# ISP_CCP2B register map
Vendor: Texas Instruments
Peripheral module from a debugger description file (folder omap36xx).
Registers are 32-bit, read-write, reset values left out (the file's numbers can be read two ways) unless marked. A register's access mark holds for its fields unless they carry their own. Offsets are as the file gives them; lines under a group give offsets from that group; [hi:lo] are bit positions; {n}, {i} and the like mark numbered series; 'fields as' and 'values as' point back to an identical list; <NAME> marks a mode.

## ISP_CCP2B
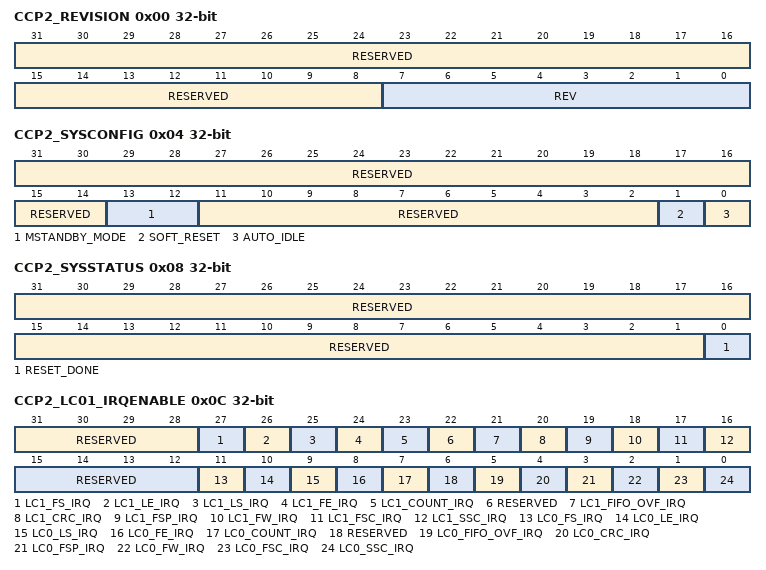
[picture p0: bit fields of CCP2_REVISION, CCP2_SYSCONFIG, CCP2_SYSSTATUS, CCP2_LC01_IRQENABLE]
0x00 CCP2_REVISION ro — MODULE REVISION This register contains the IP revision code in binary coded digital. For example, 0x01 = revision 0.1 and 0x21 = revision 2.1
  [31:8] RESERVED — Write 0's for future compatibility.Reads returns 0.
  [7:0] REV — IP revision [7:4] Major revision[3:0] Minor revision
0x04 CCP2_SYSCONFIG — SYSTEM CONFIGURATION REGISTERThis register is the Interconnect-socket system configuration register.
  [31:14] RESERVED — Write 0s for future compatibility. Read returns 0.
  [13:12] MSTANDBY_MODE — Sets the behavior of the master port power management signals
    0=Force-standby. MStandby is asserted only when the module is disabled.; 1=No-standby. MStandby is never asserted.; 2=Smart-standby: MStandby is asserted based on the activity of the module. The module tries to go to standby during the vertical blanking period.
  [11:2] RESERVED — Write 0s for future compatibility. Read returns 0.
  [1] SOFT_RESET — Software reset. Set the bit to 1 to trigger a module reset. The bit is automatically reset by the hardware. Read returns 0.
    0=Normal mode; 1=The module is reset
  [0] AUTO_IDLE — Internal Interconnect clock-gating strategy
    0=Interconnect clock is free-running; 1=Automatic Interconnect clock-gating strategy is applied based on Interconnect interface activity
0x08 CCP2_SYSSTATUS ro — SYSTEM STATUS REGISTER This register provides status information about the module, excluding interrupt status information.
  [31:1] RESERVED — Write 0s for future compatibility. Read returns 0.
  [0] RESET_DONE — Internal reset monitoring
    0=Internal module reset is ongoing; 1=Reset complete
0x0C CCP2_LC01_IRQENABLE — INTERRUPT ENABLE REGISTER - LOGICAL CHANNELS 0 and 1 This register regroups all the events related to logical channel 0 and logical channel 1. The events related to logical channel 0 trigger SINTERRUPTN[0]. The events related to logical channel 1 trigger SINTERRUPTN[1]. The channel is enabled for events to be generated on that channel.
  [31:28] RESERVED — Write 0s for future compatibility. Read returns 0.
  [27] LC1_FS_IRQ — Logical channel 1 - Frame start synchronization code detection
    0=Event is masked; 1=Event generates an interrupt when it occurs
  [26] LC1_LE_IRQ — Logical channel 1 - Line end synchronization code detection
    values as LC1_FS_IRQ
  [25] LC1_LS_IRQ — Logical channel 1 - Line start synchronization code detection
    values as LC1_FS_IRQ
  [24] LC1_FE_IRQ — Logical channel 1 - Frame end synchronization code detection
    values as LC1_FS_IRQ
  [23] LC1_COUNT_IRQ — Logical channel 1 - Frame counter reached
    values as LC1_FS_IRQ
  [22] RESERVED — Write 0s for future compatibility. Read returns 0.
  [21] LC1_FIFO_OVF_IRQ — Logical channel 1 - FIFO overflow error
    values as LC1_FS_IRQ
  [20] LC1_CRC_IRQ — Logical channel 1 - CRC error
    values as LC1_FS_IRQ
  [19] LC1_FSP_IRQ — Logical channel 1 - FSP error
    values as LC1_FS_IRQ
  [18] LC1_FW_IRQ — Logical channel 1 - Frame width error
    values as LC1_FS_IRQ
  [17] LC1_FSC_IRQ — Logical channel 1 - False synchronization code error
    values as LC1_FS_IRQ
  [16] LC1_SSC_IRQ — Logical channel 1 - Shifted synchronization code error.\This interrupt can be triggered if the PHY is set in parallel mode (CCP2_CTRL.IO_OUT_SEL = 1).
    values as LC1_FS_IRQ
  [15:12] RESERVED — Write 0s for future compatibility. Read returns 0.
  [11] LC0_FS_IRQ — Logical channel 0 - Frame start synchronization code detection
    values as LC1_FS_IRQ
  [10] LC0_LE_IRQ — Logical channel 0 - Line end synchronization code detection
    values as LC1_FS_IRQ
  [9] LC0_LS_IRQ — Logical channel 0 - Line start synchronization code detection
    values as LC1_FS_IRQ
  [8] LC0_FE_IRQ — Logical channel 0 - Frame end synchronization code detection
    values as LC1_FS_IRQ
  [7] LC0_COUNT_IRQ — Logical channel 0 - Frame counter reached
    values as LC1_FS_IRQ
  [6] RESERVED — Write 0s for future compatibility. Read returns 0.
  [5] LC0_FIFO_OVF_IRQ — Logical channel 0 - FIFO overflow error
    values as LC1_FS_IRQ
  [4] LC0_CRC_IRQ — Logical channel 0 - CRC error
    values as LC1_FS_IRQ
  [3] LC0_FSP_IRQ — Logical channel 0 - FSP error
    values as LC1_FS_IRQ
  [2] LC0_FW_IRQ — Logical channel 0 - Frame width error
    values as LC1_FS_IRQ
  [1] LC0_FSC_IRQ — Logical channel 0 - False synchronization code error
    values as LC1_FS_IRQ
  [0] LC0_SSC_IRQ — Logical channel 0 - Shifted synchronization code errorThis interrupt can be triggered if the PHY is set in parallel mode (CCP2_CTRL.IO_OUT_SEL = 1).
    values as LC1_FS_IRQ
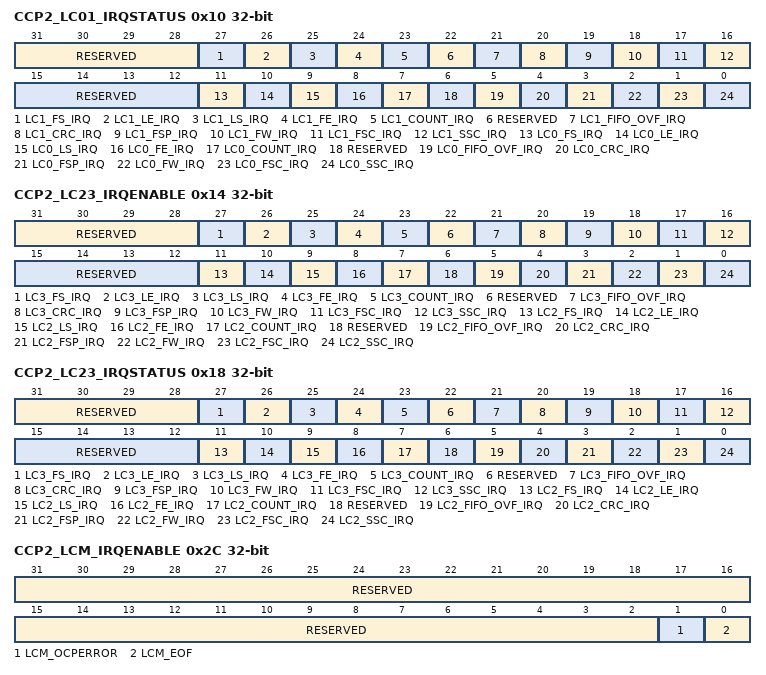
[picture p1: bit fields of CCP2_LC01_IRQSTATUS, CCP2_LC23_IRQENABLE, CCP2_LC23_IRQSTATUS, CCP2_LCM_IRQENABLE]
0x10 CCP2_LC01_IRQSTATUS access not given — INTERRUPT STATUS REGISTER - LOGICAL CHANNELS 0 and 1 This register regroups all the events related to logical channel 0 and logical channel 1. The events related to logical channel 0 trigger SINTERRUPTN[0]. The events related to logical channel 1 trigger SINTERRUPTN[1]. The channel is enabled for events to be generated on that channel.
  [31:28] RESERVED rw — Write 0s for future compatibility. Read returns 0.
  [27] LC1_FS_IRQ — Logical channel 1 - Frame start synchronization code detection status (access RW 1toClr)
    0=READS: Event is false. WRITES: Status bit unchanged; 1=READS: Event is true (pending). WRITES: Status bit is reset.
  [26] LC1_LE_IRQ — Logical channel 1 - Line end synchronization code detection status (access RW 1toClr)
    values as LC1_FS_IRQ
  [25] LC1_LS_IRQ — Logical channel 1 - Line start synchronization code detection status (access RW 1toClr)
    values as LC1_FS_IRQ
  [24] LC1_FE_IRQ — Logical channel 1 - Frame end synchronization code detection status (access RW 1toClr)
    values as LC1_FS_IRQ
  [23] LC1_COUNT_IRQ — Logical channel 1 - Frame counter reached status (access RW 1toClr)
    values as LC1_FS_IRQ
  [22] RESERVED rw — Write 0s for future compatibility. Read returns 0.
  [21] LC1_FIFO_OVF_IRQ — Logical channel 1 - FIFO overflow error status (access RW 1toClr)
    values as LC1_FS_IRQ
  [20] LC1_CRC_IRQ — Logical channel 1 - CRC error status (access RW 1toClr)
    values as LC1_FS_IRQ
  [19] LC1_FSP_IRQ — Logical channel 1 - FSP error status (access RW 1toClr)
    values as LC1_FS_IRQ
  [18] LC1_FW_IRQ — Logical channel 1 - Frame width error status (access RW 1toClr)
    values as LC1_FS_IRQ
  [17] LC1_FSC_IRQ — Logical channel 1 - False synchronization code error status (access RW 1toClr)
    values as LC1_FS_IRQ
  [16] LC1_SSC_IRQ — Logical channel 1 - Shifted synchronization code error status (access RW 1toClr)
    values as LC1_FS_IRQ
  [15:12] RESERVED rw — Write 0s for future compatibility. Read returns 0.
  [11] LC0_FS_IRQ — Logical channel 0 - Frame start synchronization code detection status (access RW 1toClr)
    values as LC1_FS_IRQ
  [10] LC0_LE_IRQ — Logical channel 0 - Line end synchronization code detection status (access RW 1toClr)
    values as LC1_FS_IRQ
  [9] LC0_LS_IRQ — Logical channel 0 - Line start synchronization code detection status (access RW 1toClr)
    values as LC1_FS_IRQ
  [8] LC0_FE_IRQ — Logical channel 0 - Frame end synchronization code detection status (access RW 1toClr)
    values as LC1_FS_IRQ
  [7] LC0_COUNT_IRQ — Logical channel 0 - Frame counter reached status (access RW 1toClr)
    values as LC1_FS_IRQ
  [6] RESERVED rw — Write 0s for future compatibility. Read returns 0.
  [5] LC0_FIFO_OVF_IRQ — Logical channel 0 - FIFO overflow error status (access RW 1toClr)
    values as LC1_FS_IRQ
  [4] LC0_CRC_IRQ — Logical channel 0 - CRC error status (access RW 1toClr)
    values as LC1_FS_IRQ
  [3] LC0_FSP_IRQ — Logical channel 0 - FSP error status (access RW 1toClr)
    values as LC1_FS_IRQ
  [2] LC0_FW_IRQ — Logical channel 0 - Frame width error status (access RW 1toClr)
    values as LC1_FS_IRQ
  [1] LC0_FSC_IRQ — Logical channel 0 - False synchronization code error status (access RW 1toClr)
    values as LC1_FS_IRQ
  [0] LC0_SSC_IRQ — Logical channel 0 - Shifted synchronization code error status (access RW 1toClr)
    values as LC1_FS_IRQ
0x14 CCP2_LC23_IRQENABLE — INTERRUPT ENABLE REGISTER - LOGICAL CHANNELS 2 and 3 This register regroups all the events related to logical channel 2 and logical channel 3. The events related to logical channel 2 trigger SINTERRUPTN[2]. The events related to logical channel 3 trigger SINTERRUPTN[3]. The channel is enabled for events to be generated on that channel.
  [31:28] RESERVED — Write 0s for future compatibility. Read returns 0.
  [27] LC3_FS_IRQ — Logical channel 3 - Frame start synchronization code detection
    values as CCP2_LC01_IRQENABLE.LC1_FS_IRQ
  [26] LC3_LE_IRQ — Logical channel 3 - Line end synchronization code detection
    values as CCP2_LC01_IRQENABLE.LC1_FS_IRQ
  [25] LC3_LS_IRQ — Logical channel 3 - Line start synchronization code detection
    values as CCP2_LC01_IRQENABLE.LC1_FS_IRQ
  [24] LC3_FE_IRQ — Logical channel 3 - Frame end synchronization code detection
    values as CCP2_LC01_IRQENABLE.LC1_FS_IRQ
  [23] LC3_COUNT_IRQ — Logical channel 3 - Frame counter reached
    values as CCP2_LC01_IRQENABLE.LC1_FS_IRQ
  [22] RESERVED — Write 0s for future compatibility. Read returns 0.
  [21] LC3_FIFO_OVF_IRQ — Logical channel 3 - FIFO overflow error
    values as CCP2_LC01_IRQENABLE.LC1_FS_IRQ
  [20] LC3_CRC_IRQ — Logical channel 3 - CRC error
    values as CCP2_LC01_IRQENABLE.LC1_FS_IRQ
  [19] LC3_FSP_IRQ — Logical channel 3 - FSP error
    values as CCP2_LC01_IRQENABLE.LC1_FS_IRQ
  [18] LC3_FW_IRQ — Logical channel 3 - Frame width error
    values as CCP2_LC01_IRQENABLE.LC1_FS_IRQ
  [17] LC3_FSC_IRQ — Logical channel 3 - False synchronization code error
    values as CCP2_LC01_IRQENABLE.LC1_FS_IRQ
  [16] LC3_SSC_IRQ — Logical channel 3 - Shifted synchronization code errorThis interrupt can be triggered if the PHY is set in parallel mode (CCP2_CTRL.IO_OUT_SEL = 1).
    values as CCP2_LC01_IRQENABLE.LC1_FS_IRQ
  [15:12] RESERVED — Write 0s for future compatibility. Read returns 0.
  [11] LC2_FS_IRQ — Logical channel 2 - Frame start synchronization code detection
    values as CCP2_LC01_IRQENABLE.LC1_FS_IRQ
  [10] LC2_LE_IRQ — Logical channel 2 - Line end synchronization code detection
    values as CCP2_LC01_IRQENABLE.LC1_FS_IRQ
  [9] LC2_LS_IRQ — Logical channel 2 - Line start synchronization code detection
    values as CCP2_LC01_IRQENABLE.LC1_FS_IRQ
  [8] LC2_FE_IRQ — Logical channel 2 - Frame end synchronization code detection
    values as CCP2_LC01_IRQENABLE.LC1_FS_IRQ
  [7] LC2_COUNT_IRQ — Logical channel 2 - Frame counter reached
    values as CCP2_LC01_IRQENABLE.LC1_FS_IRQ
  [6] RESERVED — Write 0s for future compatibility. Read returns 0.
  [5] LC2_FIFO_OVF_IRQ — Logical channel 2 - FIFO overflow error
    values as CCP2_LC01_IRQENABLE.LC1_FS_IRQ
  [4] LC2_CRC_IRQ — Logical channel 2 - CRC error
    values as CCP2_LC01_IRQENABLE.LC1_FS_IRQ
  [3] LC2_FSP_IRQ — Logical channel 2 - FSP error
    values as CCP2_LC01_IRQENABLE.LC1_FS_IRQ
  [2] LC2_FW_IRQ — Logical channel 2 - Frame width error
    values as CCP2_LC01_IRQENABLE.LC1_FS_IRQ
  [1] LC2_FSC_IRQ — Logical channel 2 - False synchronization code error
    values as CCP2_LC01_IRQENABLE.LC1_FS_IRQ
  [0] LC2_SSC_IRQ — Logical channel 2 - Shifted synchronization code errorThis interrupt can be triggered if the PHY is set in parallel mode (CCP2_CTRL.IO_OUT_SEL = 1).
    values as CCP2_LC01_IRQENABLE.LC1_FS_IRQ
0x18 CCP2_LC23_IRQSTATUS access not given — INTERRUPT STATUS REGISTER - LOGICAL CHANNELS 2 and 3 This register regroups all the events related to logical channel 2 and logical channel 3. The events related to logical channel 2 trigger SINTERRUPTN[2]. The events related to logical channel 3 trigger SINTERRUPTN[3]. The channel is enabled for events to be generated on that channel.
  [31:28] RESERVED rw — Write 0s for future compatibility. Read returns 0.
  [27] LC3_FS_IRQ — Logical channel 3 - Frame start synchronization code detection status (access RW 1toClr)
    values as CCP2_LC01_IRQSTATUS.LC1_FS_IRQ
  [26] LC3_LE_IRQ — Logical channel 3 - Line end synchronization code detection status (access RW 1toClr)
    values as CCP2_LC01_IRQSTATUS.LC1_FS_IRQ
  [25] LC3_LS_IRQ — Logical channel 3 - Line start synchronization code detection status (access RW 1toClr)
    values as CCP2_LC01_IRQSTATUS.LC1_FS_IRQ
  [24] LC3_FE_IRQ — Logical channel 3 - Frame end synchronization code detection status (access RW 1toClr)
    values as CCP2_LC01_IRQSTATUS.LC1_FS_IRQ
  [23] LC3_COUNT_IRQ — Logical channel 3 - Frame counter reached status (access RW 1toClr)
    values as CCP2_LC01_IRQSTATUS.LC1_FS_IRQ
  [22] RESERVED rw — Write 0s for future compatibility. Read returns 0.
  [21] LC3_FIFO_OVF_IRQ — Logical channel 3 - FIFO overflow error status (access RW 1toClr)
    values as CCP2_LC01_IRQSTATUS.LC1_FS_IRQ
  [20] LC3_CRC_IRQ — Logical channel 3 - CRC error status (access RW 1toClr)
    values as CCP2_LC01_IRQSTATUS.LC1_FS_IRQ
  [19] LC3_FSP_IRQ — Logical channel 3 - FSP error status (access RW 1toClr)
    values as CCP2_LC01_IRQSTATUS.LC1_FS_IRQ
  [18] LC3_FW_IRQ — Logical channel 3 - Frame width error status (access RW 1toClr)
    values as CCP2_LC01_IRQSTATUS.LC1_FS_IRQ
  [17] LC3_FSC_IRQ — Logical channel 3 - False synchronization code error status (access RW 1toClr)
    values as CCP2_LC01_IRQSTATUS.LC1_FS_IRQ
  [16] LC3_SSC_IRQ — Logical channel 3 - Shifted synchronization code error status (access RW 1toClr)
    values as CCP2_LC01_IRQSTATUS.LC1_FS_IRQ
  [15:12] RESERVED rw — Write 0s for future compatibility. Read returns 0.
  [11] LC2_FS_IRQ — Logical channel 2 - Frame start synchronization code detection status (access RW 1toClr)
    values as CCP2_LC01_IRQSTATUS.LC1_FS_IRQ
  [10] LC2_LE_IRQ — Logical channel 2 - Line end synchronization code detection status (access RW 1toClr)
    values as CCP2_LC01_IRQSTATUS.LC1_FS_IRQ
  [9] LC2_LS_IRQ — Logical channel 2 - Line start synchronization code detection status (access RW 1toClr)
    values as CCP2_LC01_IRQSTATUS.LC1_FS_IRQ
  [8] LC2_FE_IRQ — Logical channel 2 - Frame end synchronization code detection status (access RW 1toClr)
    values as CCP2_LC01_IRQSTATUS.LC1_FS_IRQ
  [7] LC2_COUNT_IRQ — Logical channel 2 - Frame counter reached status (access RW 1toClr)
    values as CCP2_LC01_IRQSTATUS.LC1_FS_IRQ
  [6] RESERVED rw — Write 0s for future compatibility. Read returns 0.
  [5] LC2_FIFO_OVF_IRQ — Logical channel 2 - FIFO overflow error status (access RW 1toClr)
    values as CCP2_LC01_IRQSTATUS.LC1_FS_IRQ
  [4] LC2_CRC_IRQ — Logical channel 2 - CRC error status (access RW 1toClr)
    values as CCP2_LC01_IRQSTATUS.LC1_FS_IRQ
  [3] LC2_FSP_IRQ — Logical channel 2 - FSP error status (access RW 1toClr)
    values as CCP2_LC01_IRQSTATUS.LC1_FS_IRQ
  [2] LC2_FW_IRQ — Logical channel 2 - Frame width error status (access RW 1toClr)
    values as CCP2_LC01_IRQSTATUS.LC1_FS_IRQ
  [1] LC2_FSC_IRQ — Logical channel 2 - False synchronization code error status (access RW 1toClr)
    values as CCP2_LC01_IRQSTATUS.LC1_FS_IRQ
  [0] LC2_SSC_IRQ — Logical channel 2 - Shifted synchronization code error status (access RW 1toClr)
    values as CCP2_LC01_IRQSTATUS.LC1_FS_IRQ
0x2C CCP2_LCM_IRQENABLE — INTERRUPT ENABLE REGISTER - Memory channel. This register regroups all the events related to memory channel 2. The events related to the memory channel trigger SINTERRUPTN[8]. The channel is enabled for events to be generated on that channel.
  [31:2] RESERVED — Write 0s for future compatibility. Read returns 0.
  [1] LCM_OCPERROR — An Interconnect error occurred on the master read port.
    values as CCP2_LC01_IRQENABLE.LC1_FS_IRQ
  [0] LCM_EOF — Memory read channel - End of frame
    values as CCP2_LC01_IRQENABLE.LC1_FS_IRQ
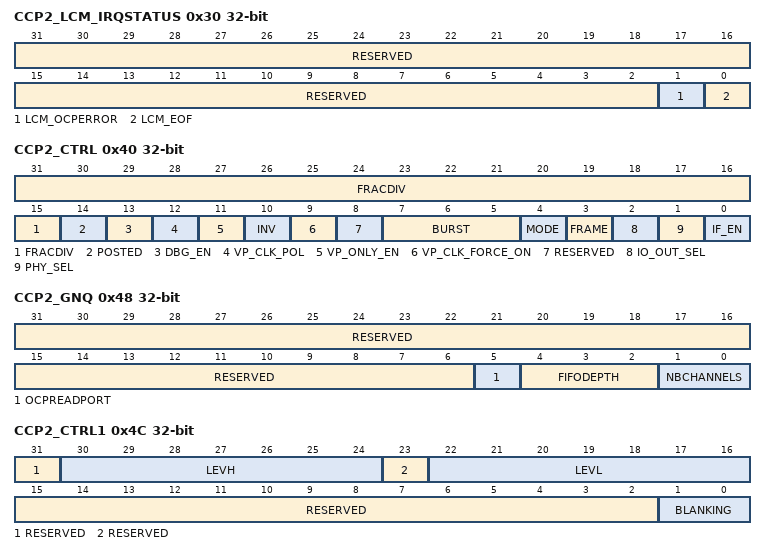
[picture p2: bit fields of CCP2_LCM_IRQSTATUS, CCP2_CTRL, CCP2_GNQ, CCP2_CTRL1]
0x30 CCP2_LCM_IRQSTATUS access not given — INTERRUPT STATUS REGISTER - Memory channel. This register regroups all the events related to memory channel. The events related to the memory channel trigger SINTERRUPTN[8]. The channel is enabled for events to be generated on that channel.
  [31:2] RESERVED rw — Write 0s for future compatibility. Read returns 0.
  [1] LCM_OCPERROR — An Interconnect error occurred on the master read port. (access RW 1toClr)
    values as CCP2_LC01_IRQSTATUS.LC1_FS_IRQ
  [0] LCM_EOF — Memory read channel - End of frame (access RW 1toClr)
    values as CCP2_LC01_IRQSTATUS.LC1_FS_IRQ
0x40 CCP2_CTRL access not given — GLOBAL CONTROL REGISTER. This register controls the CCP2B RECEIVER module. This register is not modified dynamically (except IF_EN bit field).
  [31:15] FRACDIV rw — Fractional clock divider control for the video port.The means video port clock is VPBASECLOCK * FRACDIV/65536. .
  [14] POSTED rw — Selects between posted and nonposted writes
    0=Nonposted; 1=Posted
  [13] DBG_EN — Enables the debug mode
    0=Disable; 1=Enable
  [12] VP_CLK_POL rw — VP clock polarity
    0=The CCP2B RECEIVER module writes the data on the VP on the pixel clock falling edge. The module connected to the VP samples the data on the pixel clock rising edge.; 1=The CCP2B RECEIVER module writes the data on the VP on the pixel clock raising edge. The module connected to the VP samples the data on the pixel clock falling edge.
  [11] VP_ONLY_EN rw — VP only enable
    0=The VP is enabled and the Interconnect master port is enabled; 1=The VP is enabled and the Interconnect master port is disabled. The embedded data and pixel data are output on the VP.
  [10] INV rw — Strobe/clock inversion control signal
    0=Not inverted; 1=Inverted
  [9] VP_CLK_FORCE_ON rw — Controls video port clock gating during frame blanking periods.
    0=The video port clock is gated during vertical blanking periods; 1=The video port clock is free-running during vertical blanking periods
  [8] RESERVED ro — Write 0s for future compatibility. Read returns 0.
  [7:5] BURST rw — Forces the write burst size used by the moduleThe write burst size must never exceed the output FIFO size. The output FIFO size can be read with the CCP2_GNQ.FIFODEPTH bit field.
    0=1 x 64-bit burst = single request; 1=2 x 64-bit bursts; 2=4 x 64-bit bursts; 3=8 x 64-bit bursts; 4=16 x 64-bit bursts
  [4] MODE rw — Selects the receiver operating mode
    0=MIPI CSI1-compatible mode. When this bit is set, all CCP2B settings are ignored. If the settings are not set correctly to MIPI CSI1 values, the behavior of the receiver is unpredictable.; 1=CCP2B compatible mode
  [3] FRAME rw — Set the modality in which IF_EN works.
    0=When SW writes IF_EN = 0, the interface is disabled immediately; 1=When SW writes IF_EN = 0, the interface is disabled after the next FEC synchronization code
  [2] IO_OUT_SEL rw — IO cell output mode selection
    1=MUST BE SET TO 1, IO output is parallel: DATA32, DATATOG, SYNTOG. The SSC_IRQ error can be triggered in this configuration.
  [1] PHY_SEL rw — Physical layer protocol selection. Applies for all logical channels
    0=Data/clock physical layer; 1=Data/strobe physical layer
  [0] IF_EN rw — Enables the physical interface to the module
    0=The interface is disabled. If FRAME = 0, it is disabled immediately. If FRAME = 1, it is disabled on the next FEC synchronization code. If FRAME=1, it is advised to disable the logical channels (CCP2_LCX_CTRL.CHAN_EN = 0) before writing IF_EN = 0.; 1=The interface is enabled immediately, the data acquisition starts on the next FSC synchronization code. Writing 1 to this register when the current value is 0 clears the output FIFO. The pixel data of the following frame is written in the PING buffer; that is, the CCP2_LCX_CTRL.PING_PONG bits are also reset to 1.
0x44 CCP2_DBG wo — DEBUG REGISTER This register provides a way to debug the CCP2B RECEIVER module with no image sensor connected to the module. The debug mode is enabled by.DBG_EN. Each write to this register provides a full 32-bit word to the CCP2B RECEIVER, even when only 8 or 16 bits are written. The newly written value is merged with the previous value (check the example in , CCP2 Receiver Basic Programming Model).
  [31:0] DBG — 32-bit input value.Write-only register. Read returns 0.
0x48 CCP2_GNQ ro — GENERIC PARAMETER REGISTER This register provide a way to read the generic parameters used in the design.
  [31:6] RESERVED — Write 0s for future compatibility. Read returns 0.
  [5] OCPREADPORT — The Interconnect master read port, the DPCM encoder and ALAW decompression are only present when this bit is set.
  [4:2] FIFODEPTH — Output FIFO size in multiple of 64 bits.
    0=FIFODEPTH_0_r (2x 64 bits); 1=FIFODEPTH_1_r (4x 64 bits); 2=FIFODEPTH_2_r (8x 64 bits); 3=FIFODEPTH_3_r (16x 64 bits); 4=FIFODEPTH_4_r (32x 64 bits); 5=FIFODEPTH_5_r (64x 64 bits)
  [1:0] NBCHANNELS — Number of logical channels supported by the module.
    0=NBCHANNELS_0_r (1 logical channel); 1=NBCHANNELS_1_r (2 logical channels); 2=NBCHANNELS_2_r (4 logical channels); 3=NBCHANNELS_3_r (8 logical channels)
0x4C CCP2_CTRL1 access per field — Global control register (2)
  [31] RESERVED ro — Write 0s for future compatibility. Read returns 0.
  [30:24] LEVH rw — Controls generation of MFlag[1:0]:Allowed values 0..FIFO_SIZE .
    0=FIFO_LEV=LEVL; 10=LEVLFIFO_LEV and FIFO_LEV=LEVH; 11=LEVHFIFO_LEV
  [23] RESERVED ro — Write 0s for future compatibility. Read returns 0.
  [22:16] LEVL rw — Controls generation of MFlag[1:0]:Allowed values 0..FIFO_SIZE .
    values as LEVH
  [15:2] RESERVED ro — Write 0s for future compatibility. Read returns 0.
  [1:0] BLANKING rw — Controls the number of clock pulses provided during vertical and horizontal clock periodsWhen the blanking period provided by the camera is lower than the value set here, the blanking period is shortened by the CCP2_RECEIVER to prevent internal FIFO overflow. Software must increase the sensor blanking period in that case. .
    0=4 video port clock cycles; 1=16 video port clock cycles; 2=64 video port clock cycles; 3=Free-running
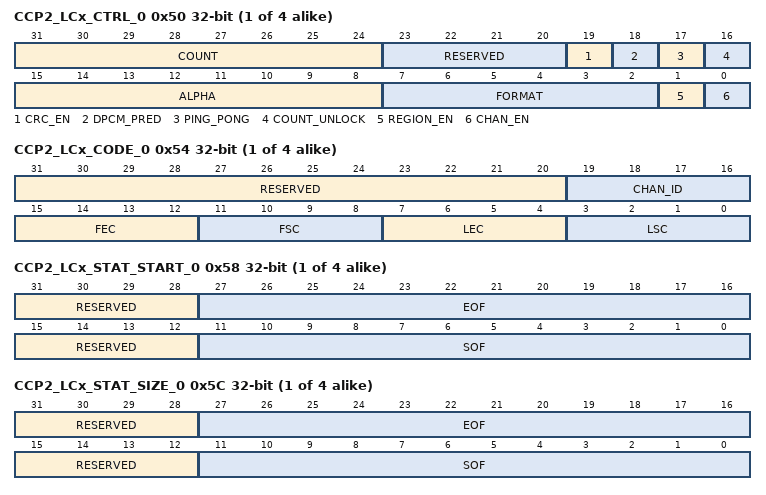
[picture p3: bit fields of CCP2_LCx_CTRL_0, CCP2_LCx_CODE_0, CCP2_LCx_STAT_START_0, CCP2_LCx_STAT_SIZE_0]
{0x50+0x30*i} CCP2_LCx_CTRL_{i} access per field (i=0..3) — CONTROL REGISTER - LOGICAL CHANNEL x. This register controls logical channel x. This register is shadowed; modifications are taken into account after the next FSC synchronization code.
  [31:24] COUNT rw — Sets the number of frame to acquire. Once the frame acquisition starts, the COUNT value is decremented after every frame. When COUNT reaches 0, the COUNT_IRQ interrupt is triggered and CHAN_EN is set to '0'. Writes to this bit field are controlled by the COUNT_UNLOCK bit. COUNT can be overwritten dynamically with a new count value. 0: Infinite number of frames (no count).1: 1 frame to acquire...255: 255 frames to acquire.
  [23:20] RESERVED ro — Write 0s for future compatibility. Read returns 0.
  [19] CRC_EN rw — Enables the cyclic redundancy check.
    0=Disabled; 1=Enabled
  [18] DPCM_PRED rw — Selects the DPCM predictor to be used for the RAW6+DPCM10, RAW7+DPCM10 and RAW8+DPCM12 data formats.The RAW8+DPCM10 data format always use the simple predictor.
    0=The advanced predictor is used; 1=The simple predictor is used
  [17] PING_PONG ro — Indicates whether the PING or PONG destination address (CCP2_LC0_DAT_PING_ADDR or CCP2_LC0_DAT_PONG_ADDR) was used to write the last frame. This bit field toggles after every FEC sync code.
    0=PING_PONG_0_r (PING buffer); 1=PING_PONG_1_r (PONG buffer)
  [16] COUNT_UNLOCK wo — Unlock writes to the COUNT bit field.
    0=COUNT_UNLOCK_0_w (COUNT bit field is locked. Writes have no effect); 1=COUNT_UNLOCK_1_w (COUNT bit field is unlocked. Writes are possible.)
  [15:8] ALPHA rw — Alpha value for RGB888 and RBG444.
  [7:2] FORMAT rw — Data format selection.
    0=YUV422 BIG ENDIAN; 1=YUV422 LITTLE ENDIAN; 2=YUV420; 3=YUV422 + VP or RAW8 + VP; 4=RGB444 + EXP16; 5=RGB565; 6=RGB888; 7=RGB888 + EXP32; 8=RAW6 + EXP8; 9=RAW6 + DPCM10 + EXP16; 10=RAW6 + DPCM10 + VP; 11=RAW10 - RAW6 DPCMRAW10 data from sensor is DPCM compressed into RAW6 before it is send to memory.Used predictor is selected by the DPCM_PRED bit; 12=RAW7 + EXP8; 13=RAW7 + DPCM10 + EXP16; 14=RAW7 + DPCM10 + VP; 15=RAW10 - RAW6 DPCM + EXP8RAW10 data from sensor is DPCM compressed into RAW6 and expanded to 8 bits before it is send to memory.Used predictor is selected by the DPCM_PRED bit; 16=RAW8 This mode can be used to output RAW6 and RAW7 as well; 17=RAW8 + DPCM10 + EXP16; 18=RAW8 + DPCM10 + VP; 19=RAW10 - RAW7 DPCMRAW10 data from sensor is DPCM compressed into RAW7 before it is send to memory.Used predictor is selected by the DPCM_PRED bit; 20=RAW10; 21=RAW10 + EXP16; 22=RAW10 + VP; 23=RAW10 - RAW7 DPCM + EXP8RAW10 data from sensor is DPCM compressed into RAW7 and expanded to 8 bits before it is send to memory.Used predictor is selected by the DPCM_PRED bit; 24=RAW12; 25=RAW12 + EXP16; 26=RAW12 + VP; 27=RAW10 - RAW8 DPCMRAW10 data from sensor is DPCM compressed into RAW8 before it is send to memory; 28=JPEG8 + FSP; 29=JPEG8; 30=RAW10 - RAW8RAW10 data from sensor is right shifted to produce RAW8 before it is send to memory; 31=RAW8 DPCM12 - RAW12 + VPUsed predictor is selected by the DPCM_PRED bit; 32=RAW10 - RAW8 ALAW; 33=RAW8 DPCM10 - ALAW
  [1] REGION_EN rw — Enables the setting of regions of interest in the frame: SOF region, EOF region and DAT region.
    0=Disabled; 1=Enabled
  [0] CHAN_EN rw — Enables the logical channel
{0x54+0x30*i} CCP2_LCx_CODE_{i} (i=0..3) — CODE REGISTER - LOGICAL CHANNEL x. This register sets the codes that are used in the 32-bit synchronization codes to recognize the logical channel, frame start, frame end, line start, and line end codes. This register applies for logical channel x only. The default values should not be modified. Updating this register with new codes under a flowing serial transmission on that channel causes unexpected results.
  [31:20] RESERVED — Write 0s for future compatibility. Read returns 0.
  [19:16] CHAN_ID — Logical channel x identifierThe channel identifier is located between bits 4 to 7 in the 32-bit synchronization codes.
  [15:12] FEC — Logical channel x frame end synchronization code identifierThe synchronization code identifier is between bits 0 to 3 in the 32-bit synchronization codes.
  [11:8] FSC — Logical channel x frame start synchronization code identifierThe synchronization code identifier is between bits 0 to 3 in the 32-bit synchronization codes.
  [7:4] LEC — Logical channel x line end synchronization code identifierThe synchronization code identifier is between bits 0 to 3 in the 32-bit synchronization codes.
  [3:0] LSC — Logical channel x line start synchronization code identifierThe synchronization code identifier is between bits 0 to 3 in the 32-bit synchronization codes.
{0x58+0x30*i} CCP2_LCx_STAT_START_{i} (i=0..3) — STATUS LINE START REGISTER - LOGICAL CHANNEL x. This register is shadowed; modifications are taken into account after the next FSC synchronization code.
  [31:28] RESERVED — Write 0s for future compatibility. Read returns 0.
  [27:16] EOF — Sets the vertical position of the EOF status lines in reference to the FSC synchronization code. From 0 to 4095.
  [15:12] RESERVED — Write 0s for future compatibility. Read returns 0.
  [11:0] SOF — Sets the vertical position of the EOF status lines in reference to the FSC synchronization code. Should always be 0.
{0x5C+0x30*i} CCP2_LCx_STAT_SIZE_{i} (i=0..3) — STATUS LINE SIZE REGISTER - LOGICAL CHANNEL x. This register is shadowed; modifications are taken into account after the next FSC synchronization code.
  [31:28] RESERVED — Write 0s for future compatibility. Read returns 0.
  [27:16] EOF — Sets the number of EOF status linesFrom 0 to 4095
  [15:12] RESERVED — Write 0s for future compatibility. Read returns 0.
  [11:0] SOF — Sets the number of SOF status line(s)From 0 to 4095
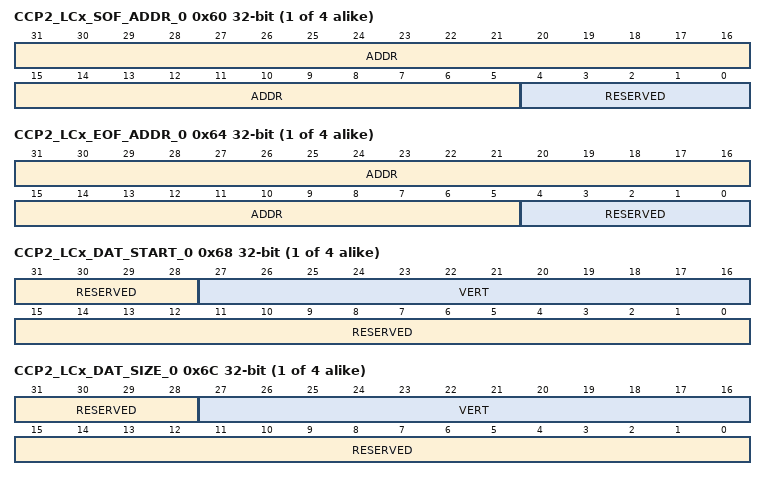
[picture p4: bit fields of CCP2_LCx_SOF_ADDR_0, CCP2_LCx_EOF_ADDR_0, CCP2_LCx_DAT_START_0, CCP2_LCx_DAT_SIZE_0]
{0x60+0x30*i} CCP2_LCx_SOF_ADDR_{i} (i=0..3) — SOF STATUS LINE MEMORY ADDRESS REGISTER - LOGICAL CHANNEL x. This register sets the 32-bit memory address where the SOF data are stored. The 5 LSBs are ignored; the address is aligned on a 32-byte boundary. This register is shadowed; modifications are taken into account after the next FSC synchronization code.
  [31:5] ADDR — 27 MSBs of the 32-bit address
  [4:0] RESERVED — 5 LSBs of the 32-bit addressWrite 0s for future compatibility. Read returns 0.
{0x64+0x30*i} CCP2_LCx_EOF_ADDR_{i} (i=0..3) — EOF STATUS LINE MEMORY ADDRESS REGISTER - LOGICAL CHANNEL x. This register sets the 32-bit memory address where the EOF data are stored. The 5 LSBs are ignored; the address is aligned on a 32-byte boundary. This register is shadowed; modifications are taken into account after the next FSC synchronization code.
  fields as CCP2_LCx_SOF_ADDR_0
{0x68+0x30*i} CCP2_LCx_DAT_START_{i} (i=0..3) — DATA START REGISTER - LOGICAL CHANNEL x. This register is shadowed; modifications are taken into account after the next FSC synchronization code.
  [31:28] RESERVED — Write 0s for future compatibility. Read returns 0.
  [27:16] VERT — Sets the vertical position of the data in reference to the FSC synchronization code. From 0 to 4095 lines.
  [15:0] RESERVED — Write 0s for future compatibility. Read returns 0.
{0x6C+0x30*i} CCP2_LCx_DAT_SIZE_{i} (i=0..3) — DATA SIZE REGISTER - LOGICAL CHANNEL x. This register is shadowed; modifications are taken into account after the next FSC synchronization code.
  [31:28] RESERVED — Write 0s for future compatibility. Read returns 0.
  [27:16] VERT — Sets the vertical size of the data windowFrom 0 to 4095 lines. If VERT = 0, no data are output.
  [15:0] RESERVED — Write 0s for future compatibility. Read returns 0.
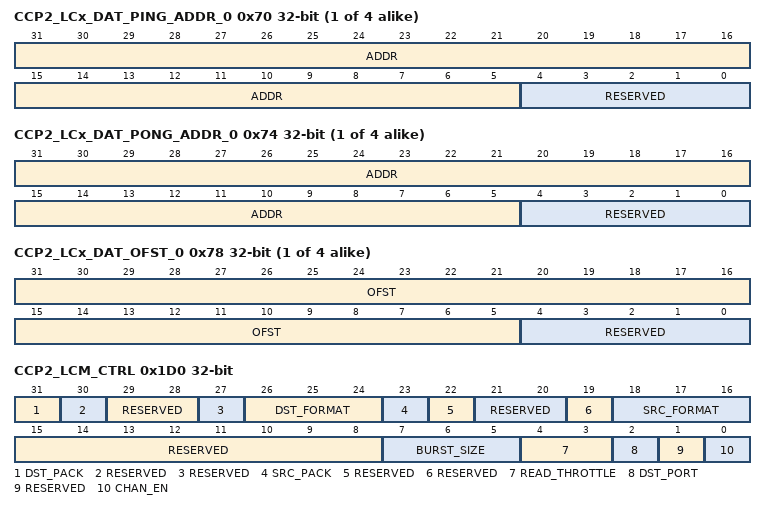
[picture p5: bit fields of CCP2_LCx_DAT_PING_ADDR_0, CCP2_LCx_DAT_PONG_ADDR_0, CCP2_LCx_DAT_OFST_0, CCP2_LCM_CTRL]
{0x70+0x30*i} CCP2_LCx_DAT_PING_ADDR_{i} (i=0..3) — DATA MEMORY PING ADDRESS REGISTER - LOGICAL CHANNEL x. This register sets the 32-bit memory address where the pixel data are stored. The destination is double-buffered; this register sets the PING address. Double-buffering is enabled when the addresses CCP2_LC0_DAT_PING_ADDR and CCP2_LC0_DAT_PONG_ADDR are different. The 5 LSBs are ignored; the address is aligned on a 32-byte boundary. This register is shadowed; modifications are taken into account after the next FSC synchronization code.
  fields as CCP2_LCx_SOF_ADDR_0
{0x74+0x30*i} CCP2_LCx_DAT_PONG_ADDR_{i} (i=0..3) — DATA MEMORY PONG ADDRESS REGISTER - LOGICAL CHANNEL x. This register sets the 32-bit memory address where the pixel data are stored. The destination is double-buffered; this register sets the PONG address. Double-buffering is enabled when the addresses CCP2_LC0_DAT_PING_ADDR and CCP2_LC0_DAT_PONG_ADDR are different. The 5 LSBs are ignored; the address is aligned on a 32-byte boundary. This register is shadowed; modifications are taken into account after the next FSC synchronization code.
  fields as CCP2_LCx_SOF_ADDR_0
{0x78+0x30*i} CCP2_LCx_DAT_OFST_{i} (i=0..3) — DATA MEMORY ADDRESS OFFSET REGISTER - LOGICAL CHANNEL x. This register sets the offset, which is applied on the destination address after each line is written to memory. This register applies for both and . For example, it enables 2D data transfers of the pixel data into a frame buffer. In such case, the pixel data and frame buffer data have the same data format. Note that the 5 LSBs are ignored: the offset shall be a multiple of 32 bytes. The use of this register is limited to the following data formats: YUV422 little-endian, YUV422 big-endian, RGB565, RGB444 + EXP16, RGB888 + EXP32. This register is shadowed; modifications are taken into account after the next FSC synchronization code.
  [31:5] OFST — Line offset programmed in bytesIf OFST = 0, the data are written contiguously in memory. Otherwise, OFST sets the destination offset between the first pixel of the previous line and the first pixel of the current line.
  [4:0] RESERVED — Write 0s for future compatibility. Read returns 0.
0x1D0 CCP2_LCM_CTRL — Control register for the memory channel. It defines the data format of the source frame stored in memory and how this frame is processed.
  [31] DST_PACK — Data is packed before it is sent to memory.Applies to RAW6, RAW7, RAW10, and RAW12 only. .
    0=Disabled; 1=Enabled
  [30] RESERVED — Write 0s for future compatibility. Read returns 0.
  [29:28] RESERVED — Write 0s for future compatibility. Read returns 0.
  [27] RESERVED — Write 0s for future compatibility. Read returns 0.
  [26:24] DST_FORMAT — Output format selectionNot every combination of input and output formats is possible. See ,
    0=RAW6; 1=RAW7; 2=RAW8; 3=RAW10; 4=RAW12; 5=RAW14; 6=RAW16
  [23] SRC_PACK — Data stored in memory is packed and must be unpacked.
    0=Disabled; 1=Enabled
  [22] RESERVED — Write 0s for future compatibility. Read returns 0.
  [21:20] RESERVED — Write 0s for future compatibility. Read returns 0.
  [19] RESERVED — Write 0s for future compatibility. Read returns 0.
  [18:16] SRC_FORMAT — Data format of the data stored in memoryBecause there is no header embedded in the data sent to memory, the user is responsible for choosing the correct format.
    0=RAW6; 1=RAW7; 2=RAW8; 3=RAW10; 4=RAW12; 5=RAW14; 6=RAW16
  [15:8] RESERVED — Write 0s for future compatibility. Read returns 0.
  [7:5] BURST_SIZE — Defines the burst size of the master read port
    0=1x 64-bit burst = single request; 1=2x 64-bit bursts; 2=4x 64-bit bursts; 3=8x 64-bit bursts; 4=16x 64-bit bursts; 5=32x 64-bit bursts
  [4:3] READ_THROTTLE — Limit maximum data read speed for memory-to-memory operation.
    0=Full speed. Throughput is limited by internal processing capabilities.; 1=1/2 speed; 2=1/4 speed; 3=1/8 speed
  [2] DST_PORT — Select the destination port.
    0=Data is sent to video port; it is always sent without compression or packing. The.DST_PACK, and registers have no effect.; 1=Data is sent to memory
  [1] RESERVED — Write 0s for future compatibility. Read returns 0.
  [0] CHAN_EN — Enables the read from the memory channelBefore enabling the memory read channel, the software must:- Disable the physical interface using the IF_EN bit- Wait until disabling of the physical interface is effective (depends on the FRAME bit)Read from memory starts when this bit is set; therefore, all CCP2_LCM_x registers must be configured correctly before the bit is set.This bit is cleared by hardware at the end of the frame.
    0=Disabled; 1=Enabled
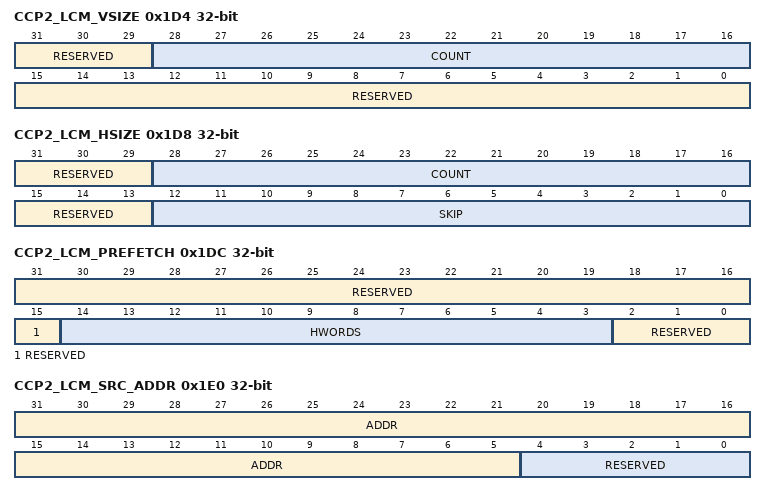
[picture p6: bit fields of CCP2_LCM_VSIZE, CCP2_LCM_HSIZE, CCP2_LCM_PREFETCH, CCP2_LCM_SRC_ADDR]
0x1D4 CCP2_LCM_VSIZE — Memory channel vertical framing register
  [31:29] RESERVED — Write 0s for future compatibility. Read returns 0.
  [28:16] COUNT — Defines the line count to be read from memoryFrom 1 to 8191 lines.
  [15:0] RESERVED — Write 0s for future compatibility. Read returns 0.
0x1D8 CCP2_LCM_HSIZE — Memory read channel horizontal framing register
  [31:29] RESERVED — Write 0s for future compatibility. Read returns 0.
  [28:16] COUNT — Horizontal count of pixels to output after the skipped pixelsValid values: 1–8191
  [15:13] RESERVED — Write 0s for future compatibility. Read returns 0.
  [12:0] SKIP — Horizontal count of pixels to skip after the start of the line.Valid values: 0–81910 disables pixel skipping
0x1DC CCP2_LCM_PREFETCH — This register defines the amount of data to be fetched from memory. It must be consistent with the register (see , CCP2 Receiver Basic Programming Model).
  [31:15] RESERVED — Write 0s for future compatibility. Read returns 0.
  [14:3] HWORDS — 64-bit words to read from memory for each line of the imagePossible values: 1 to 4095
  [2:0] RESERVED — Write 0s for future compatibility. Read returns 0.
0x1E0 CCP2_LCM_SRC_ADDR — Memory channel source address register This register sets the 32-bit memory address where the pixel data are stored. The 5 LSBs are ignored; the address is aligned on a 32-byte boundary.
  fields as CCP2_LCx_SOF_ADDR_0
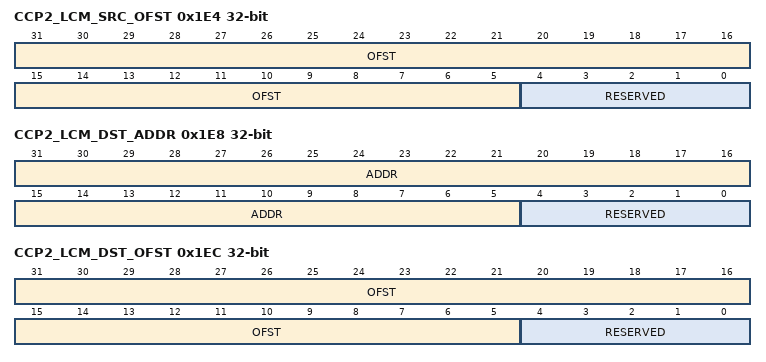
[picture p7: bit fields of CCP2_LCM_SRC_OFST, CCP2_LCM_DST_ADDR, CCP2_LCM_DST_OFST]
0x1E4 CCP2_LCM_SRC_OFST — Memory channel source offset register. This register sets the offset, which is applied on the source address after each line is read from memory. For example, it enables 2D data transfers of the pixel data from a frame buffer. In such case, the pixel data and frame buffer data have the same data format. The 5 LSBs are ignored; the offset is a multiple of 32 bytes.
  [31:5] OFST — Line offset programmed in bytesIf OFST = 0, the data are read contiguously from memory. Otherwise, OFST sets the source offset between the first pixel of the previous line and the first pixel of the current line.
  [4:0] RESERVED — Write 0s for future compatibility. Read returns 0.
0x1E8 CCP2_LCM_DST_ADDR — Memory channel destination address. This register sets the 32-bit memory address where the pixel data are stored. The 5 LSBs are ignored; the address is aligned on a 32-byte boundary.
  [31:5] ADDR — 27 MSBs of the 32-bit address.
  [4:0] RESERVED — 5 least significant bits of the 32-bit addressWrite 0s for future compatibility. Read returns 0.
0x1EC CCP2_LCM_DST_OFST — Memory channel destination offset register. This register sets the offset, which is applied on the destination address after each line is written to memory. For example, it enables 2D data transfers of the pixel data into a frame buffer. In such case, the pixel data and frame buffer data have the same data format. The 5 LSBs are ignored; the offset is a multiple of 32 bytes.
  [31:5] OFST — Line offset programmed in bytesIf OFST = 0, the data are written contiguously to memory if possible. At the end of a line, only full 32-bit words are written, eventually creating gaps at the end of lines.Otherwise, OFST sets the destination offset between the first pixel of the previous line and the first pixel of the current line.
  [4:0] RESERVED — Write 0s for future compatibility. Read returns 0.
